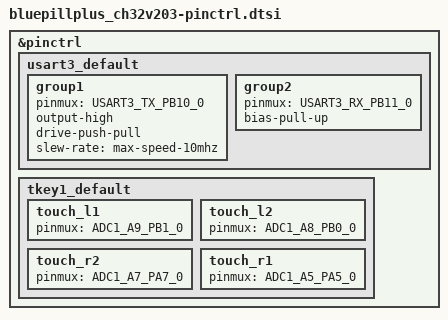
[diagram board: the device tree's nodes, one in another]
/*
 * Copyright (c) 2025 MASSDRIVER EI (massdriver.space)
 * SPDX-License-Identifier: Apache-2.0
 */

#include <zephyr/dt-bindings/pinctrl/ch32v20x_30x-pinctrl.h>

&pinctrl {
	usart3_default: usart3_default {
		group1 {
			pinmux = <USART3_TX_PB10_0>;
			output-high;
			drive-push-pull;
			slew-rate = "max-speed-10mhz";
		};

		group2 {
			pinmux = <USART3_RX_PB11_0>;
			bias-pull-up;
		};
	};

	tkey1_default: tkey1_default {
		touch_l1 {
			pinmux = <ADC1_A9_PB1_0>;
		};

		touch_l2 {
			pinmux = <ADC1_A8_PB0_0>;
		};

		touch_r2 {
			pinmux = <ADC1_A7_PA7_0>;
		};

		touch_r1 {
			pinmux = <ADC1_A5_PA5_0>;
		};
	};
};
